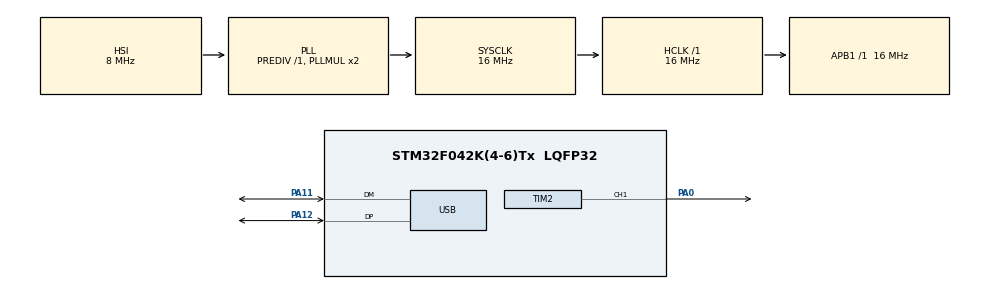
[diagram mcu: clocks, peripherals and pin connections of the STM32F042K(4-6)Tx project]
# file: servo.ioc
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Mcu.Family=STM32F0
Mcu.Name=STM32F042K(4-6)Tx
Mcu.Package=LQFP32
NVIC.TIM2_IRQn=true\:0\:0\:false\:false\:true\:true\:true
NVIC.USB_IRQn=true\:0\:0\:false\:false\:true\:false\:true
PA0.Signal=S_TIM2_CH1_ETR
PA11.Mode=Device
PA11.Signal=USB_DM
PA12.Mode=Device
PA12.Signal=USB_DP
ProjectManager.HeapSize=0x10
ProjectManager.StackSize=0x400
ProjectManager.TargetToolchain=MDK-ARM V5.32
RCC.AHBFreq_Value=16000000
RCC.APB1Freq_Value=16000000
RCC.APB1TimFreq_Value=16000000
RCC.HCLKFreq_Value=16000000
RCC.SYSCLKFreq_VALUE=16000000
RCC.SYSCLKSource=RCC_SYSCLKSOURCE_PLLCLK
SH.S_TIM2_CH1_ETR.0=TIM2_CH1,PWM Generation1 CH1
TIM2.Channel-PWM\ Generation1\ CH1=TIM_CHANNEL_1
TIM2.Period=1000-1
TIM2.Prescaler=320-1
USB_DEVICE.APP_RX_DATA_SIZE=128
USB_DEVICE.APP_TX_DATA_SIZE=128
USB_DEVICE.CLASS_NAME_FS=CDC
USB_DEVICE.VirtualMode=Cdc
USB_DEVICE.VirtualModeFS=Cdc_FS
VP_TIM2_VS_ClockSourceINT.Mode=Internal
VP_USB_DEVICE_VS_USB_DEVICE_CDC_FS.Mode=CDC_FS
board=NUCLEO-F042K6

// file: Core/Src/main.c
/* USER CODE BEGIN Header */
/**
  ******************************************************************************
  * @file           : main.c
  * @brief          : Main program body
  ******************************************************************************
  * @attention
  *
  * Copyright (c) 2022 STMicroelectronics.
  * All rights reserved.
  *
  * This software is licensed under terms that can be found in the LICENSE file
  * in the root directory of this software component.
  * If no LICENSE file comes with this software, it is provided AS-IS.
  *
  ******************************************************************************
  */
/* USER CODE END Header */
#include "main.h"
#include "usb_device.h"

/* USER CODE BEGIN Includes */
#include "usbd_cdc_if.h"
#include "string.h"
/* USER CODE END Includes */

TIM_HandleTypeDef htim2;

void SystemClock_Config(void);
static void MX_GPIO_Init(void);
static void MX_TIM2_Init(void);

/* USER CODE BEGIN 0 */
char *data = "Hello, World!\r\n";
uint8_t buffer[64];
/* USER CODE END 0 */

int main(void)
{
  /* USER CODE BEGIN 1 */
	uint8_t buffer_prev[64];
  /* USER CODE END 1 */

  /* MCU Configuration--------------------------------------------------------*/

  /* Reset of all peripherals, Initializes the Flash interface and the Systick. */
  HAL_Init();

  /* Configure the system clock */
  SystemClock_Config();

  /* Initialize all configured peripherals */
  MX_GPIO_Init();
  MX_TIM2_Init();
  MX_USB_DEVICE_Init();
  /* USER CODE BEGIN 2 */
	HAL_TIM_PWM_Start(&htim2, TIM_CHANNEL_1); // start the PWM
  /* USER CODE END 2 */

  /* Infinite loop */
  /* USER CODE BEGIN WHILE */
	HAL_Delay(1000);
	CDC_Transmit_FS((uint8_t*)data, strlen(data));
  while (1)
  {
    /* USER CODE END WHILE */

    /* USER CODE BEGIN 3 */
		if(strcmp((char*)buffer,(char*)buffer_prev)){
			strcpy((char*)buffer_prev, (char*)buffer);
			CDC_Transmit_FS((uint8_t*)buffer_prev, strlen((const char*)buffer_prev));

		}

		//HAL_Delay(1000);

//		htim2.Instance->CCR1 = 25;  // Duty Cycle= 0.5ms/(1/50Hz), rotate angle= -90°
//	  HAL_Delay(1000);
//	  htim2.Instance->CCR1 = 75;  // Duty Cycle= 1.5ms/(1/50Hz), rotate angle= 0°
//	  HAL_Delay(1000);
//	  htim2.Instance->CCR1 = 125; // Duty Cycle= 2.5ms/(1/50Hz), rotate angle= 90°
//	  HAL_Delay(1000);
  }
  /* USER CODE END 3 */
}

void SystemClock_Config(void)
{
  RCC_OscInitTypeDef RCC_OscInitStruct = {0};
  RCC_ClkInitTypeDef RCC_ClkInitStruct = {0};
  RCC_PeriphCLKInitTypeDef PeriphClkInit = {0};

  /** Initializes the RCC Oscillators according to the specified parameters
  * in the RCC_OscInitTypeDef structure.
  */
  RCC_OscInitStruct.OscillatorType = RCC_OSCILLATORTYPE_HSI|RCC_OSCILLATORTYPE_HSI48;
  RCC_OscInitStruct.HSIState = RCC_HSI_ON;
  RCC_OscInitStruct.HSI48State = RCC_HSI48_ON;
  RCC_OscInitStruct.HSICalibrationValue = RCC_HSICALIBRATION_DEFAULT;
  RCC_OscInitStruct.PLL.PLLState = RCC_PLL_ON;
  RCC_OscInitStruct.PLL.PLLSource = RCC_PLLSOURCE_HSI;
  RCC_OscInitStruct.PLL.PLLMUL = RCC_PLL_MUL2;
  RCC_OscInitStruct.PLL.PREDIV = RCC_PREDIV_DIV1;
  if (HAL_RCC_OscConfig(&RCC_OscInitStruct) != HAL_OK)
  {
    Error_Handler();
  }
  /** Initializes the CPU, AHB and APB buses clocks
  */
  RCC_ClkInitStruct.ClockType = RCC_CLOCKTYPE_HCLK|RCC_CLOCKTYPE_SYSCLK
                              |RCC_CLOCKTYPE_PCLK1;
  RCC_ClkInitStruct.SYSCLKSource = RCC_SYSCLKSOURCE_PLLCLK;
  RCC_ClkInitStruct.AHBCLKDivider = RCC_SYSCLK_DIV1;
  RCC_ClkInitStruct.APB1CLKDivider = RCC_HCLK_DIV1;

  if (HAL_RCC_ClockConfig(&RCC_ClkInitStruct, FLASH_LATENCY_0) != HAL_OK)
  {
    Error_Handler();
  }
  PeriphClkInit.PeriphClockSelection = RCC_PERIPHCLK_USB;
  PeriphClkInit.UsbClockSelection = RCC_USBCLKSOURCE_HSI48;

  if (HAL_RCCEx_PeriphCLKConfig(&PeriphClkInit) != HAL_OK)
  {
    Error_Handler();
  }
}

static void MX_TIM2_Init(void)
{

  TIM_ClockConfigTypeDef sClockSourceConfig = {0};
  TIM_MasterConfigTypeDef sMasterConfig = {0};
  TIM_OC_InitTypeDef sConfigOC = {0};

  htim2.Instance = TIM2;
  htim2.Init.Prescaler = 320-1;
  htim2.Init.CounterMode = TIM_COUNTERMODE_UP;
  htim2.Init.Period = 1000-1;
  htim2.Init.ClockDivision = TIM_CLOCKDIVISION_DIV1;
  htim2.Init.AutoReloadPreload = TIM_AUTORELOAD_PRELOAD_DISABLE;
  if (HAL_TIM_Base_Init(&htim2) != HAL_OK)
  {
    Error_Handler();
  }
  sClockSourceConfig.ClockSource = TIM_CLOCKSOURCE_INTERNAL;
  if (HAL_TIM_ConfigClockSource(&htim2, &sClockSourceConfig) != HAL_OK)
  {
    Error_Handler();
  }
  if (HAL_TIM_PWM_Init(&htim2) != HAL_OK)
  {
    Error_Handler();
  }
  sMasterConfig.MasterOutputTrigger = TIM_TRGO_RESET;
  sMasterConfig.MasterSlaveMode = TIM_MASTERSLAVEMODE_DISABLE;
  if (HAL_TIMEx_MasterConfigSynchronization(&htim2, &sMasterConfig) != HAL_OK)
  {
    Error_Handler();
  }
  sConfigOC.OCMode = TIM_OCMODE_PWM1;
  sConfigOC.Pulse = 0;
  sConfigOC.OCPolarity = TIM_OCPOLARITY_HIGH;
  sConfigOC.OCFastMode = TIM_OCFAST_DISABLE;
  if (HAL_TIM_PWM_ConfigChannel(&htim2, &sConfigOC, TIM_CHANNEL_1) != HAL_OK)
  {
    Error_Handler();
  }
  HAL_TIM_MspPostInit(&htim2);

}

static void MX_GPIO_Init(void)
{

  /* GPIO Ports Clock Enable */
  __HAL_RCC_GPIOA_CLK_ENABLE();

}

void Error_Handler(void)
{
  __disable_irq();
  while (1)
  {
  }
}
